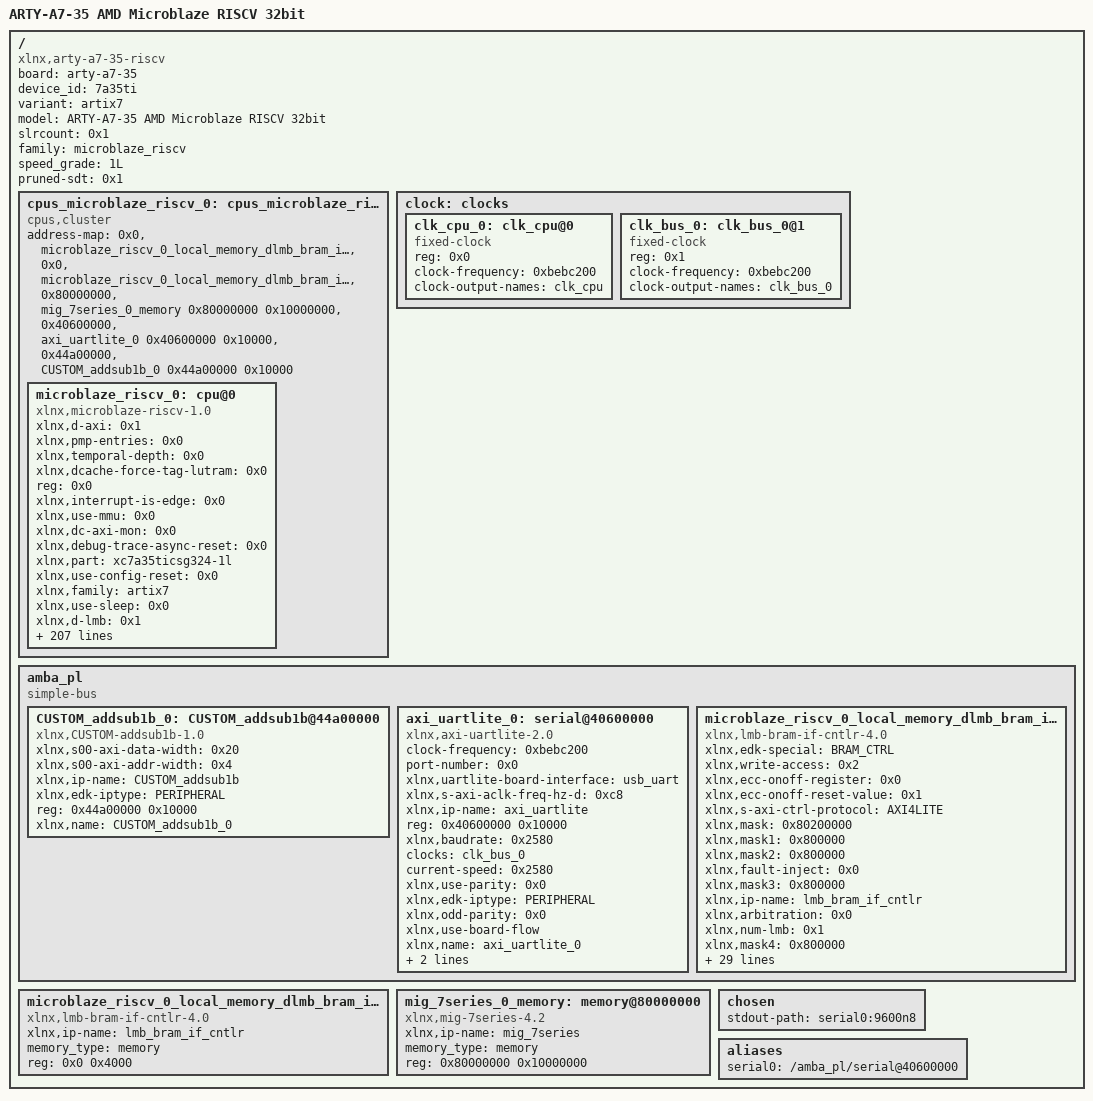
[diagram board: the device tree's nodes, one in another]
/dts-v1/;
/ {
        board = "arty-a7-35";
        compatible = "xlnx,arty-a7-35-riscv", "qemu,mbv", "amd,mbv";
        device_id = "7a35ti";
        #address-cells = <0x1>;
        variant = "artix7";
        model = "ARTY-A7-35 AMD Microblaze RISCV 32bit";
        #size-cells = <0x1>;
        slrcount = <0x1>;
        family = "microblaze_riscv";
        speed_grade = "1L";
        pruned-sdt = <0x1>;

        cpus_microblaze_riscv_0: cpus_microblaze_riscv@0 {
                phandle = <0x9>;
                #cpu-mask-cells = <0x1>;
                compatible = "cpus,cluster";
                #address-cells = <0x1>;
                bootph-all;
                #size-cells = <0x0>;
                address-map = <0x0 &microblaze_riscv_0_local_memory_dlmb_bram_if_cntlr_memory 0x0 0x4000>,
                 <0x0 &microblaze_riscv_0_local_memory_dlmb_bram_if_cntlr 0x0 0x4000>,
                 <0x80000000 &mig_7series_0_memory 0x80000000 0x10000000>,
                 <0x40600000 &axi_uartlite_0 0x40600000 0x10000>,
                 <0x44a00000 &CUSTOM_addsub1b_0 0x44a00000 0x10000>;
                #ranges-address-cells = <0x1>;
                #ranges-size-cells = <0x1>;

                microblaze_riscv_0: cpu@0 {
                        phandle = <0xa>;
                        xlnx,d-axi = <0x1>;
                        xlnx,pmp-entries = <0x0>;
                        xlnx,temporal-depth = <0x0>;
                        xlnx,dcache-force-tag-lutram = <0x0>;
                        reg = <0x0>;
                        xlnx,interrupt-is-edge = <0x0>;
                        xlnx,use-mmu = <0x0>;
                        xlnx,dc-axi-mon = <0x0>;
                        xlnx,debug-trace-async-reset = <0x0>;
                        xlnx,part = "xc7a35ticsg324-1l";
                        xlnx,use-config-reset = <0x0>;
                        xlnx,family = "artix7";
                        xlnx,use-sleep = <0x0>;
                        xlnx,d-lmb = <0x1>;
                        xlnx,enable-discrete-ports = <0x0>;
                        xlnx,debug-interface = <0x0>;
                        xlnx,use-ext-brk = <0x0>;
                        xlnx,debug-enabled = <0x1>;
                        xlnx,daddr-size = <0x20>;
                        xlnx,use-extended-fsl-instr = <0x0>;
                        xlnx,branch-target-cache-size = <0x0>;
                        bus-handle = <&amba_pl>;
                        xlnx,pmp-addr0 = <0x0>;
                        xlnx,pmp-addr1 = <0x0>;
                        xlnx,pmp-addr2 = <0x0>;
                        xlnx,pmp-addr3 = <0x0>;
                        xlnx,pmp-addr4 = <0x0>;
                        xlnx,edk-special = "microblaze_riscv";
                        xlnx,use-dcache = <0x0>;
                        xlnx,pmp-addr5 = <0x0>;
                        xlnx,use-muldiv = <0x0>;
                        xlnx,pmp-addr6 = <0x0>;
                        xlnx,use-axi-dp-ext-addr = <0x0>;
                        xlnx,pmp-addr7 = <0x0>;
                        xlnx,pmp-addr8 = <0x0>;
                        xlnx,pmp-addr9 = <0x0>;
                        xlnx,i-axi = <0x0>;
                        xlnx,icache-streams = <0x0>;
                        xlnx,use-embedded = <0x0>;
                        xlnx,i-lmb-has-prot = <0x0>;
                        xlnx,num-sync-ff-dbg-clk = <0x1>;
                        xlnx,icache-byte-size = <0x2000>;
                        xlnx,pmp-addr10 = <0x0>;
                        d-cache-size = <0x2000>;
                        xlnx,pmp-addr11 = <0x0>;
                        xlnx,pmp-addr12 = <0x0>;
                        xlnx,pmp-addr13 = <0x0>;
                        xlnx,pmp-addr14 = <0x0>;
                        xlnx,pmp-addr15 = <0x0>;
                        bootph-all;
                        xlnx,avoid-primitives = <0x0>;
                        xlnx,pmp-addr16 = <0x0>;
                        xlnx,pmp-addr17 = <0x0>;
                        xlnx,pmp-addr18 = <0x0>;
                        xlnx,pdaddr-size = <0x20>;
                        xlnx,pmp-addr19 = <0x0>;
                        xlnx,pmp-addr20 = <0x0>;
                        xlnx,pmp-addr21 = <0x0>;
                        xlnx,i-lmb = <0x1>;
                        xlnx,pmp-addr22 = <0x0>;
                        xlnx,lmb-data-size = <0x20>;
                        xlnx,lockstep-select = <0x0>;
                        xlnx,pmp-addr23 = <0x0>;
                        timebase-frequency = <0xbebc200>;
                        xlnx,pmp-addr24 = <0x0>;
                        xlnx,dcache-data-width = <0x0>;
                        xlnx,icache-force-tag-lutram = <0x0>;
                        xlnx,pmp-addr25 = <0x0>;
                        xlnx,use-branch-target-cache = <0x0>;
                        xlnx,pmp-addr26 = <0x0>;
                        xlnx,pmp-addr27 = <0x0>;
                        xlnx,number-of-pc-brk = <0x1>;
                        xlnx,pmp-addr28 = <0x0>;
                        xlnx,imprecise-exceptions = <0x0>;
                        xlnx,pmp-addr29 = <0x0>;
                        xlnx,pmp-addr30 = <0x0>;
                        xlnx,pmp-addr31 = <0x0>;
                        xlnx,pmp-addr32 = <0x0>;
                        model = "microblaze_riscv,1.0";
                        xlnx,pmp-addr33 = <0x0>;
                        xlnx,pmp-addr34 = <0x0>;
                        xlnx,pmp-addr35 = <0x0>;
                        xlnx,pmp-addr36 = <0x0>;
                        d-cache-highaddr = <0x3fffffff>;
                        xlnx,optimization = <0x0>;
                        xlnx,pmp-addr37 = <0x0>;
                        xlnx,pmp-addr38 = <0x0>;
                        xlnx,pmp-addr39 = <0x0>;
                        xlnx,pmp-addr40 = <0x0>;
                        xlnx,pmp-addr41 = <0x0>;
                        xlnx,d-lmb-mon = <0x0>;
                        xlnx,pmp-addr42 = <0x0>;
                        xlnx,pmp-addr43 = <0x0>;
                        xlnx,pmp-addr44 = <0x0>;
                        xlnx,pmp-addr45 = <0x0>;
                        xlnx,pmp-addr46 = <0x0>;
                        xlnx,pmp-addr47 = <0x0>;
                        xlnx,pmp-addr48 = <0x0>;
                        xlnx,fault-tolerant = <0x0>;
                        xlnx,pmp-addr49 = <0x0>;
                        xlnx,pmp-addr50 = <0x0>;
                        xlnx,pmp-addr51 = <0x0>;
                        xlnx,pmp-enhancements = <0x0>;
                        d-cache-line-size = <0x10>;
                        xlnx,mmu-privileged-instr = <0x0>;
                        xlnx,pmp-addr52 = <0x0>;
                        clock-frequency = <0xbebc200>;
                        xlnx,pmp-addr53 = <0x0>;
                        xlnx,pmp-addr54 = <0x0>;
                        xlnx,pmp-addr55 = <0x0>;
                        xlnx,i-lmb-protocol = <0x0>;
                        xlnx,pmp-addr56 = <0x0>;
                        xlnx,pmp-addr57 = <0x0>;
                        riscv,isa = "rv32i";
                        xlnx,dp-axi-mon = <0x0>;
                        xlnx,pmp-addr58 = <0x0>;
                        xlnx,pmp-addr59 = <0x0>;
                        xlnx,pmp-addr60 = <0x0>;
                        xlnx,pmp-addr61 = <0x0>;
                        xlnx,pmp-addr62 = <0x0>;
                        xlnx,pmp-addr63 = <0x0>;
                        xlnx,debug-external-trace = <0x0>;
                        xlnx,addr-size = <0x20>;
                        xlnx,debug-num-progbuf = <0x2>;
                        xlnx,debug-event-counters = <0x0>;
                        xlnx,edk-iptype = "PROCESSOR";
                        xlnx,debug-latency-counters = <0x0>;
                        xlnx,interconnect = <0x2>;
                        xlnx,edge-is-positive = <0x1>;
                        xlnx,use-icache = <0x0>;
                        xlnx,async-wakeup = <0x3>;
                        xlnx,s-axi = <0x0>;
                        xlnx,use-ext-nm-brk = <0x0>;
                        xlnx,ic-axi-mon = <0x0>;
                        xlnx,archid = <0x1>;
                        xlnx,num-sync-ff-clk-irq = <0x1>;
                        xlnx,freq = <0xbebc200>;
                        xlnx,lockstep-master = <0x0>;
                        xlnx,pmp-cfg0 = <0x0>;
                        xlnx,pmp-cfg1 = <0x0>;
                        xlnx,iaddr-size = <0x20>;
                        xlnx,interrupt-mon = <0x0>;
                        xlnx,pmp-cfg2 = <0x0>;
                        xlnx,number-of-wr-addr-brk = <0x0>;
                        xlnx,pmp-cfg3 = <0x0>;
                        xlnx,pmp-cfg4 = <0x0>;
                        xlnx,use-interrupt = <0x0>;
                        xlnx,pmp-cfg5 = <0x0>;
                        xlnx,async-interrupt = <0x1>;
                        xlnx,pc-width = <0xe>;
                        xlnx,pmp-cfg6 = <0x0>;
                        xlnx,icache-victims = <0x0>;
                        xlnx,pmp-cfg7 = <0x0>;
                        xlnx,pmp-cfg8 = <0x0>;
                        xlnx,pmp-cfg9 = <0x0>;
                        xlnx,use-bitman-a = <0x0>;
                        xlnx,use-bitman-b = <0x0>;
                        xlnx,use-bitman-c = <0x0>;
                        i-cache-baseaddr = <0x0>;
                        xlnx,i-lmb-mon = <0x0>;
                        xlnx,dcache-byte-size = <0x2000>;
                        xlnx,data-size = <0x20>;
                        compatible = "xlnx,microblaze-riscv-1.0", "amd,mbv32", "riscv", "xlnx,microblaze_riscv";
                        xlnx,pmp-debug-inhibit = <0x0>;
                        xlnx,use-sstc = <0x1>;
                        xlnx,fsl-exception = <0x0>;
                        riscv,isa-base = "rv32i";
                        xlnx,dcache-use-writeback = <0x0>;
                        device_type = "cpu";
                        xlnx,impid = <0x1>;
                        xlnx,use-bitman-s = <0x0>;
                        xlnx,base-vectors = <0x0>;
                        xlnx,icache-line-len = <0x4>;
                        xlnx,d-lmb-has-prot = <0x0>;
                        xlnx,use-barrel = <0x1>;
                        xlnx,misaligned-exceptions = <0x1>;
                        xlnx,piaddr-size = <0x20>;
                        xlnx,use-bitman = <0x0>;
                        riscv,isa-extensions = "i", "zicsr", "zifencei", "zicntr";
                        xlnx,dcache-line-len = <0x4>;
                        xlnx,num-sync-ff-clk = <0x2>;
                        i-cache-size = <0x2000>;
                        xlnx,memory-ip-list = "microblaze_riscv_0_local_memory_ilmb_bram_if_cntlr_memory", "microblaze_riscv_0_local_memory_dlmb_bram_if_cntlr_memory";
                        xlnx,number-of-rd-addr-brk = <0x0>;
                        xlnx,use-counters = <0x1>;
                        xlnx,lockstep-slave = <0x0>;
                        xlnx,pmp-cfg10 = <0x0>;
                        xlnx,pmp-cfg11 = <0x0>;
                        xlnx,debug-profile-size = <0x0>;
                        xlnx,pmp-cfg12 = <0x0>;
                        xlnx,pmp-cfg13 = <0x0>;
                        xlnx,pmp-cfg14 = <0x0>;
                        xlnx,pmp-cfg15 = <0x0>;
                        xlnx,debug-counter-width = <0x40>;
                        xlnx,icache-data-width = <0x0>;
                        xlnx,ip-name = "microblaze_riscv";
                        xlnx,ip-axi-mon = <0x0>;
                        xlnx,d-lmb-protocol = <0x0>;
                        xlnx,trace = <0x0>;
                        xlnx,ill-instr-exception = <0x2>;
                        xlnx,debug-trace-size = <0x0>;
                        xlnx,pmp-granularity = <0x2>;
                        xlnx,num-sync-ff-dbg-trace-clk = <0x2>;
                        i-cache-line-size = <0x10>;
                        xlnx,ecc-use-ce-exception = <0x0>;
                        i-cache-highaddr = <0x3fffffff>;
                        xlnx,num-sync-ff-clk-debug = <0x2>;
                        xlnx,use-atomic = <0x0>;
                        clocks = <&clk_cpu_0>;
                        xlnx,g-template-list = <0x0>;
                        xlnx,trap-enhancement = <0x0>;
                        xlnx,hartid = <0x0>;
                        xlnx,use-fpu = <0x0>;
                        xlnx,use-non-secure = <0x0>;
                        d-cache-baseaddr = <0x0>;
                        xlnx,use-compression = <0x0>;
                        xlnx,interrupt-wakeup = <0x0>;
                        xlnx,instr-size = <0x20>;
                        xlnx,fsl-links = <0x0>;
                        xlnx,dcache-victims = <0x0>;
                        xlnx,pmp-read-only = <0x0>;
                };
        };

        clock: clocks {
                phandle = <0xb>;
                #address-cells = <0x1>;
                #size-cells = <0x0>;

                clk_cpu_0: clk_cpu@0 {
                        phandle = <0x7>;
                        compatible = "fixed-clock";
                        bootph-all;
                        reg = <0x0>;
                        clock-frequency = <0xbebc200>;
                        clock-output-names = "clk_cpu";
                        #clock-cells = <0x0>;
                };

                clk_bus_0: clk_bus_0@1 {
                        phandle = <0x8>;
                        compatible = "fixed-clock";
                        bootph-all;
                        reg = <0x1>;
                        clock-frequency = <0xbebc200>;
                        clock-output-names = "clk_bus_0";
                        #clock-cells = <0x0>;
                };
        };

        amba_pl: amba_pl {
                phandle = <0x6>;
                ranges;
                compatible = "simple-bus";
                #address-cells = <0x1>;
                bootph-all;
                #size-cells = <0x1>;

                CUSTOM_addsub1b_0: CUSTOM_addsub1b@44a00000 {
                        phandle = <0x5>;
                        xlnx,s00-axi-data-width = <0x20>;
                        compatible = "xlnx,CUSTOM-addsub1b-1.0";
                        status = "okay";
                        xlnx,s00-axi-addr-width = <0x4>;
                        xlnx,ip-name = "CUSTOM_addsub1b";
                        xlnx,edk-iptype = "PERIPHERAL";
                        reg = <0x44a00000 0x10000>;
                        xlnx,name = "CUSTOM_addsub1b_0";
                };

                axi_uartlite_0: serial@40600000 {
                        phandle = <0x4>;
                        compatible = "xlnx,axi-uartlite-2.0", "xlnx,xps-uartlite-1.00.a";
                        bootph-all;
                        clock-frequency = <0xbebc200>;
                        port-number = <0x0>;
                        xlnx,uartlite-board-interface = "usb_uart";
                        xlnx,s-axi-aclk-freq-hz-d = <0xc8>;
                        xlnx,ip-name = "axi_uartlite";
                        reg = <0x40600000 0x10000>;
                        xlnx,baudrate = <0x2580>;
                        clocks = <&clk_bus_0>;
                        current-speed = <0x2580>;
                        device_type = "serial";
                        xlnx,use-parity = <0x0>;
                        xlnx,edk-iptype = "PERIPHERAL";
                        xlnx,odd-parity = <0x0>;
                        status = "okay";
                        xlnx,use-board-flow;
                        xlnx,name = "axi_uartlite_0";
                        xlnx,data-bits = <0x8>;
                        xlnx,parity = "No_Parity";
                };

                microblaze_riscv_0_local_memory_dlmb_bram_if_cntlr: lmb_bram_if_cntlr@0 {
                        phandle = <0x2>;
                        xlnx,edk-special = "BRAM_CTRL";
                        xlnx,write-access = <0x2>;
                        compatible = "xlnx,lmb-bram-if-cntlr-4.0", "xlnx,axi-bram-ctrl";
                        xlnx,ecc-onoff-register = <0x0>;
                        xlnx,ecc-onoff-reset-value = <0x1>;
                        xlnx,s-axi-ctrl-protocol = "AXI4LITE";
                        xlnx,mask = <0x80200000>;
                        xlnx,mask1 = <0x800000>;
                        xlnx,mask2 = <0x800000>;
                        xlnx,fault-inject = <0x0>;
                        xlnx,mask3 = <0x800000>;
                        xlnx,ip-name = "lmb_bram_if_cntlr";
                        xlnx,arbitration = <0x0>;
                        xlnx,num-lmb = <0x1>;
                        xlnx,mask4 = <0x800000>;
                        reg = <0x0 0x4000>;
                        xlnx,s-axi-ctrl-addr-width = <0x20>;
                        xlnx,mask5 = <0x800000>;
                        xlnx,ecc-status-registers = <0x0>;
                        xlnx,prot-cfg = <0xff>;
                        xlnx,mask6 = <0x800000>;
                        xlnx,lmb-protocol = <0x0>;
                        xlnx,ce-counter-width = <0x0>;
                        xlnx,prot-cfg1 = <0xff>;
                        xlnx,mask7 = <0x800000>;
                        xlnx,ecc = <0x0>;
                        xlnx,edk-iptype = "PERIPHERAL";
                        xlnx,prot-cfg2 = <0xff>;
                        xlnx,lmb-dwidth = <0x20>;
                        xlnx,interconnect = <0x0>;
                        xlnx,ce-failing-registers = <0x0>;
                        xlnx,prot-cfg3 = <0xff>;
                        xlnx,ue-failing-registers = <0x0>;
                        xlnx,prot-cfg4 = <0xff>;
                        xlnx,lmb-has-prot = <0x0>;
                        status = "okay";
                        xlnx,data-width = <0x20>;
                        xlnx,prot-cfg5 = <0xff>;
                        xlnx,s-axi-ctrl-data-width = <0x20>;
                        xlnx,prot-cfg6 = <0xff>;
                        xlnx,bram-awidth = <0x20>;
                        xlnx,prot-cfg7 = <0xff>;
                        xlnx,lmb-awidth = <0x20>;
                        xlnx,name = "microblaze_riscv_0_local_memory_dlmb_bram_if_cntlr";
                };
        };

        microblaze_riscv_0_local_memory_dlmb_bram_if_cntlr_memory: memory@0 {
                phandle = <0x1>;
                ranges = <0x0 0x0 0x4000>;
                compatible = "xlnx,lmb-bram-if-cntlr-4.0", "mmio-sram";
                #address-cells = <0x1>;
                xlnx,ip-name = "lmb_bram_if_cntlr";
                device_type = "memory";
                #size-cells = <0x1>;
                memory_type = "memory";
                reg = <0x0 0x4000>;
        };

        mig_7series_0_memory: memory@80000000 {
                phandle = <0x3>;
                compatible = "xlnx,mig-7series-4.2";
                xlnx,ip-name = "mig_7series";
                device_type = "memory";
                memory_type = "memory";
                reg = <0x80000000 0x10000000>;
        };

        chosen {
                stdout-path = "serial0:9600n8";
        };

        aliases {
                serial0 = "/amba_pl/serial@40600000";
        };

        __symbols__ {
                cpus_microblaze_riscv_0 = "/cpus_microblaze_riscv@0";
                microblaze_riscv_0 = "/cpus_microblaze_riscv@0/cpu@0";
                clock = "/clocks";
                clk_cpu_0 = "/clocks/clk_cpu@0";
                clk_bus_0 = "/clocks/clk_bus_0@1";
                amba_pl = "/amba_pl";
                CUSTOM_addsub1b_0 = "/amba_pl/CUSTOM_addsub1b@44a00000";
                axi_uartlite_0 = "/amba_pl/serial@40600000";
                microblaze_riscv_0_local_memory_dlmb_bram_if_cntlr = "/amba_pl/lmb_bram_if_cntlr@0";
                microblaze_riscv_0_local_memory_dlmb_bram_if_cntlr_memory = "/memory@0";
                mig_7series_0_memory = "/memory@80000000";
        };
};
